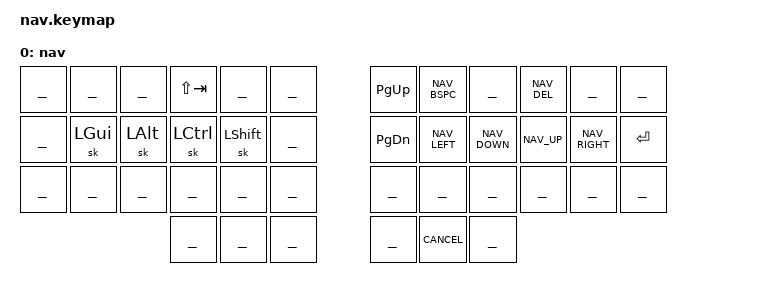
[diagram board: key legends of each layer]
ZMK_LAYER(nav,
//╭─────────────┬─────────────┬─────────────┬─────────────┬─────────────┬─────────────╮ ╭─────────────┬─────────────┬─────────────┬─────────────┬─────────────┬─────────────╮
    ___           ___           ___           &kp LS(TAB)   ___           ___             &kp PG_UP     NAV_BSPC      ___           NAV_DEL       ___           ___
//├─────────────┼─────────────┼─────────────┼─────────────┼─────────────┼─────────────┤ ├─────────────┼─────────────┼─────────────┼─────────────┼─────────────┴─────────────┤
    ___           &sk LGUI      &sk LALT      &sk LCTRL     &sk LSHFT     ___             &kp PG_DN     NAV_LEFT      NAV_DOWN      NAV_UP        NAV_RIGHT     &kp RET
//├─────────────┼─────────────┼─────────────┼─────────────┼─────────────┼─────────────┤ ├─────────────┼─────────────┼─────────────┼─────────────┼─────────────┴─────────────┤
    ___           ___           ___           ___           ___           ___             ___           ___           ___           ___           ___           ___
//╰─────────────┴─────────────┴─────────────┼─────────────┼─────────────┼─────────────┤ ├─────────────┼─────────────┼─────────────┼─────────────┴─────────────┴─────────────╯
                                              ___          ___           ___             ___           CANCEL        ___
//                                          ╰─────────────┴─────────────┴─────────────╯ ╰─────────────┴─────────────┴─────────────╯
)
